# RX64M_ICU_Pilot register map
File version: 1.0
RX64M_ICU_Pilot peripheral registers generated from iodefine.h (pilot).
Registers are 8-bit, read-write, reset 0x0 unless marked. A register's access mark holds for its fields unless they carry their own. Offsets are from the block's base; lines under a group give offsets from that group; [hi:lo] are bit positions; {n}, {i} and the like mark numbered series; 'fields as' and 'values as' point back to an identical list; <NAME> marks a mode.

## Memory map
0x00087000 ICU size 0xA02

## ICU
Base 0x00087000
{0x0+i} IR{i} (i=0..255)
  [0] IR
{0x100+i} DTCER{i} (i=0..255)
  [0] DTCE
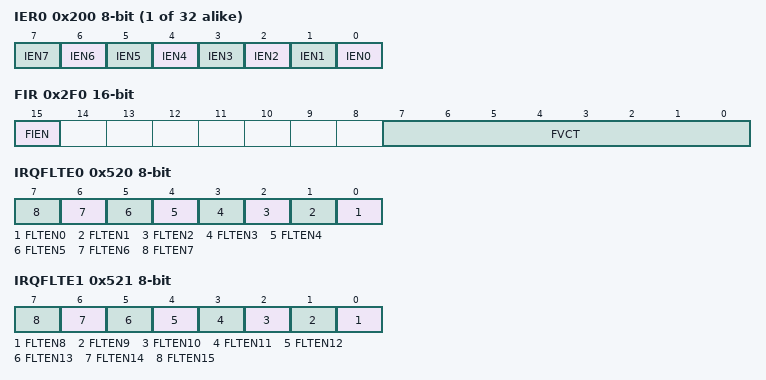
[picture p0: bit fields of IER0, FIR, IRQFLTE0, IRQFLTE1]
{0x200+i} IER{i} (i=0..31)
  [n] IEN{n} (n=0..7)
0x2E0 SWINTR
  [0] SWINT
0x2E1 SWINT2R
  [0] SWINT2
0x2F0 FIR 16-bit
  [15] FIEN, [7:0] FVCT
{0x300+i} IPR{i} (i=0..255)
  [3:0] IPR
{0x400+4i} DMRSR{i} (i=0..7)
{0x500+i} IRQCR{i} (i=0..15)
  [3:2] IRQMD
0x520 IRQFLTE0
  [n] FLTEN{n} (n=0..7)
0x521 IRQFLTE1
  [n-8] FLTEN{n} (n=8..15)
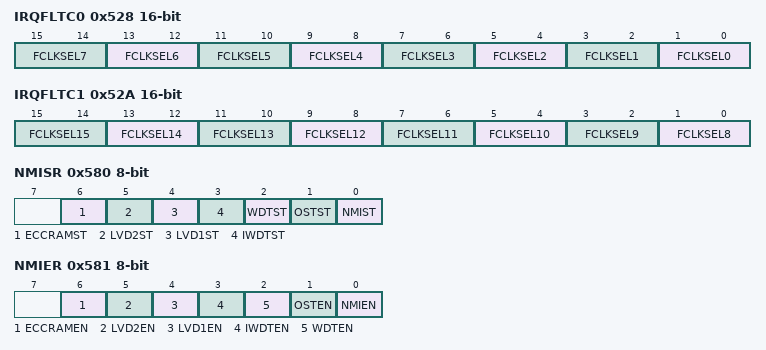
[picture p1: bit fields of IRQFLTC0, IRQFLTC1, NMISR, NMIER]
0x528 IRQFLTC0 16-bit
  [2n+1:2n] FCLKSEL{n} (n=0..7)
0x52A IRQFLTC1 16-bit
  [2n-15:2n-16] FCLKSEL{n} (n=8..15)
0x580 NMISR ro
  [6] ECCRAMST, [5] LVD2ST, [4] LVD1ST, [3] IWDTST, [2] WDTST, [1] OSTST, [0] NMIST
0x581 NMIER
  [6] ECCRAMEN, [5] LVD2EN, [4] LVD1EN, [3] IWDTEN, [2] WDTEN, [1] OSTEN, [0] NMIEN
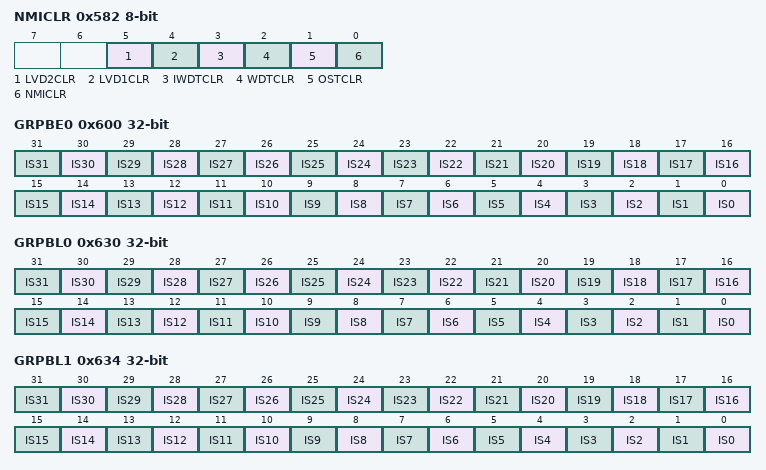
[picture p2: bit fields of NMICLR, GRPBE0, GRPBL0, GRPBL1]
0x582 NMICLR
  [5] LVD2CLR, [4] LVD1CLR, [3] IWDTCLR, [2] WDTCLR, [1] OSTCLR, [0] NMICLR
0x583 NMICR
  [3] NMIMD
0x590 NMIFLTE
  [0] NFLTEN
0x594 NMIFLTC
  [1:0] NFCLKSEL
0x600 GRPBE0 32-bit ro
  [n] IS{n} (n=0..31)
0x630 GRPBL0 32-bit ro
  [n] IS{n} (n=0..31)
0x634 GRPBL1 32-bit ro
  [n] IS{n} (n=0..31)
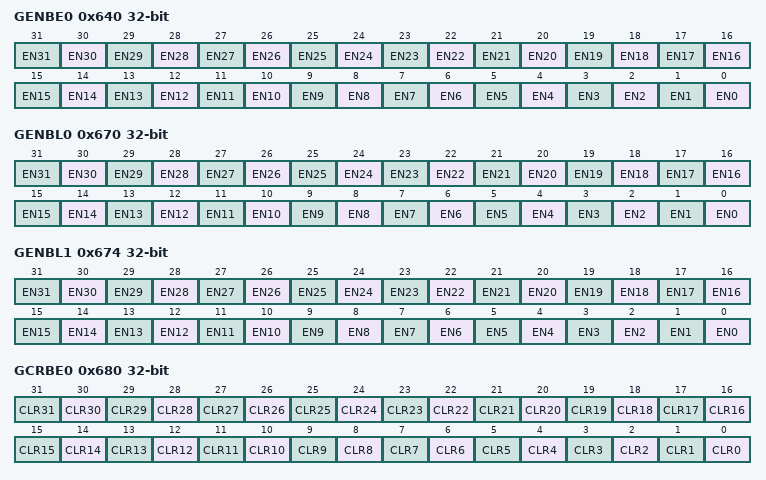
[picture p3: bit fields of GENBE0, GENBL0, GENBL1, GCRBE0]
0x640 GENBE0 32-bit
  [n] EN{n} (n=0..31)
0x670 GENBL0 32-bit
  [n] EN{n} (n=0..31)
0x674 GENBL1 32-bit
  [n] EN{n} (n=0..31)
0x680 GCRBE0 32-bit
  [n] CLR{n} (n=0..31)
{0x700+i} PIBR{i} (i=0..9)
0x70A PIBRA
{0x700+i} SLIBXR{i} (i=128..143)
  [7:0] SLI
{0x700+i} SLIBR{i} (i=144..207)
  [7:0] SLI
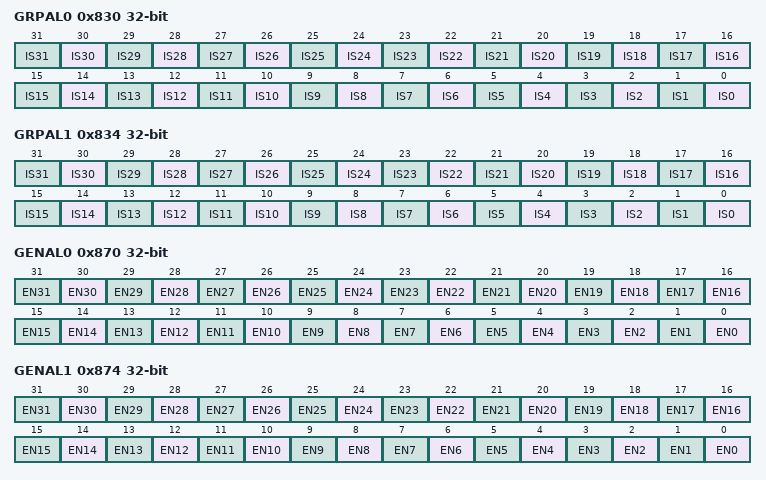
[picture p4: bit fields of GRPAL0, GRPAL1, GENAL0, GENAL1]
0x830 GRPAL0 32-bit ro
  [n] IS{n} (n=0..31)
0x834 GRPAL1 32-bit ro
  [n] IS{n} (n=0..31)
0x870 GENAL0 32-bit
  [n] EN{n} (n=0..31)
0x874 GENAL1 32-bit
  [n] EN{n} (n=0..31)
{0x900+i} PIAR{i} (i=0..9)
0x90A PIARA
0x90B PIARB
{0x900+i} SLIAR{i} (i=208..255)
  [7:0] SLI
0xA00 SLIPRCR
  [0] WPRC
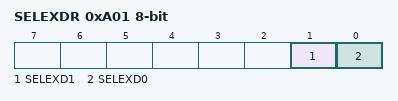
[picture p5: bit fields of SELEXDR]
0xA01 SELEXDR
  [1] SELEXD1, [0] SELEXD0
